# CORTEXA9_CPU0 register map
Vendor: Texas Instruments
Peripheral module from a debugger description file (folder omap4460).
Registers are 32-bit, access per field, reset 0x0 unless marked. A register's access mark holds for its fields unless they carry their own. Offsets are as the file gives them; lines under a group give offsets from that group; [hi:lo] are bit positions; {n}, {i} and the like mark numbered series; 'fields as' and 'values as' point back to an identical list; <NAME> marks a mode.

## CORTEXA9_CPU0
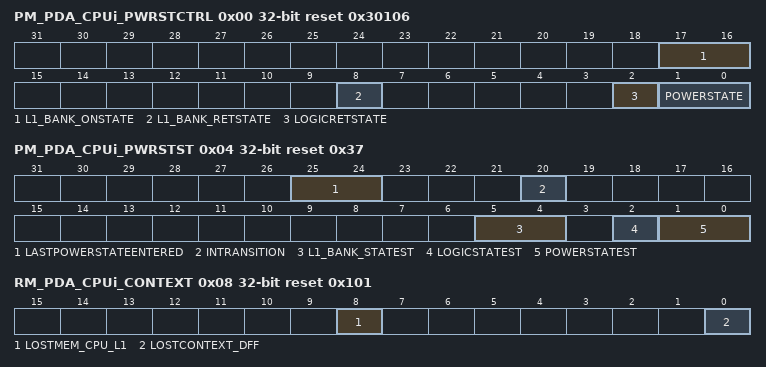
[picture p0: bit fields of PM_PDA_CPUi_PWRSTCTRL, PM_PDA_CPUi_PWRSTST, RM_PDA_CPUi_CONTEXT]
0x00 PM_PDA_CPUi_PWRSTCTRL reset 0x30106 — This register controls the CPU domain power state to reach upon a domain sleep transition
  [17:16] L1_BANK_ONSTATE ro — CPU_L1 memory state when domain is ON.
    3=L1_BANK_ONSTATE_3_r (Memory bank is on when the domain is ON.)
  [8] L1_BANK_RETSTATE ro — CPU L1 memory state when domain is RETENTION state.
    1=L1_BANK_RETSTATE_1_r (Memory bank is retained when domain is in RETENTION state.)
  [2] LOGICRETSTATE rw — Logic state control when power domain is RETENTION
    0=All CPU logic is off when the domain is in RETENTION state; 1=Whole logic is retained when domain is in RETENTION state
  [1:0] POWERSTATE rw — Power state control
    0=OFF state; 1=RETENTION state; 2=INACTIVE state; 3=ON State
0x04 PM_PDA_CPUi_PWRSTST access not given reset 0x37 — This register provides a status on the CPU domain current power state. [warm reset insensitive]
  [25:24] LASTPOWERSTATEENTERED — Last low power state entered. The software has to write 0x3 in this field to update this register. 0x0: Power domain was previously in OFF 0x1: Power domain was previously in RETENTION 0x2: Power domain was previously INACTIVE 0x3: Power domain was previously ON (access RW W1toSet)
  [20] INTRANSITION ro — Domain transition status
    0=INTRANSITION_0_r (No ongoing transition on power domain); 1=INTRANSITION_1_r (Power domain transition is in progress.)
  [5:4] L1_BANK_STATEST ro — CPU_L1 memory state status
    0=L1_BANK_STATEST_0_r (Memory is OFF); 1=L1_BANK_STATEST_1_r (Memory is RET); 2=L1_BANK_STATEST_2_r (Reserved); 3=L1_BANK_STATEST_3_r (Memory is ON)
  [2] LOGICSTATEST ro — Logic state status
    0=LOGICSTATEST_0_r (Logic in domain is OFF); 1=LOGICSTATEST_1_r (Logic in domain is ON)
  [1:0] POWERSTATEST ro — Current power state status
    0=POWERSTATEST_0_r (Power domain is OFF); 1=POWERSTATEST_1_r (Power domain is in RETENTION); 2=POWERSTATEST_2_r (Power domain is ON-INACTIVE); 3=POWERSTATEST_3_r (Power domain is ON-ACTIVE)
0x08 RM_PDA_CPUi_CONTEXT access not given reset 0x101 — This register contains dedicated CPU context statuses. [warm reset insensitive]
  [8] LOSTMEM_CPU_L1 — Specify if memory-based context in CPU_L1 memory bank has been lost due to a previous power transition or other reset source. (access RW W1toClr)
    0=Context has been maintained; 1=Context has been lost
  [0] LOSTCONTEXT_DFF — Specify if DFF-based context has been lost due to a previous power transition or other reset source. (access RW W1toClr)
    0=Context has been maintained; 1=Context has been lost
0x0C RM_PDA_CPUi_RSTCTRL — This register controls the assertion/release of the CPU CORE reset. This is basically a software warm reset (that asserts CPUx_RST) per CPU. One CPU can set this bit to reset the other CPU. Actually the CPU can set this bit to reset itself as well (and it will be kept in reset until the other active CPU clears this bit).
  [0] RST rw — CPU warm local reset control
    0=Reset is cleared; 1=Reset is asserted
0x14 CM_PDA_CPUi_CLKCTRL ro reset 0x1 — This register manages the CPU clocks.
  [0] STBYST — Module standby status. [warm reset insensitive]
    0=STBYST_0_r (Module is functional (not in standby)); 1=STBYST_1_r (Module is in standby)
0x18 CM_PDA_CPUi_CLKSTCTRL — This register enables the CPU domain power state transition. It controls the hardware-supervised domain power state transition between ON-ACTIVE and ON-INACTIVE states. It also holds 1 status bit per clock input of the domain.
  [1:0] CLKTRCTRL rw — Controls the full domain transition of the CPU domain.
    0=NO_SLEEP: Sleep transition cannot be initiated. Wake-up transition may however occur.; 1=CLKTRCTRL_1_r (Reserved); 2=Start a software forced wake-up transition on the domain. The software forced wake-up transition allows the software to wakeup a powered-down CPU by a method other than an externally triggered interrupt.; 3=HW_AUTO: Automatic transition is enabled. Sleep and wake-up transition are based upon hardware conditions. WFI triggers the sleep transition based on settings in and registers.
